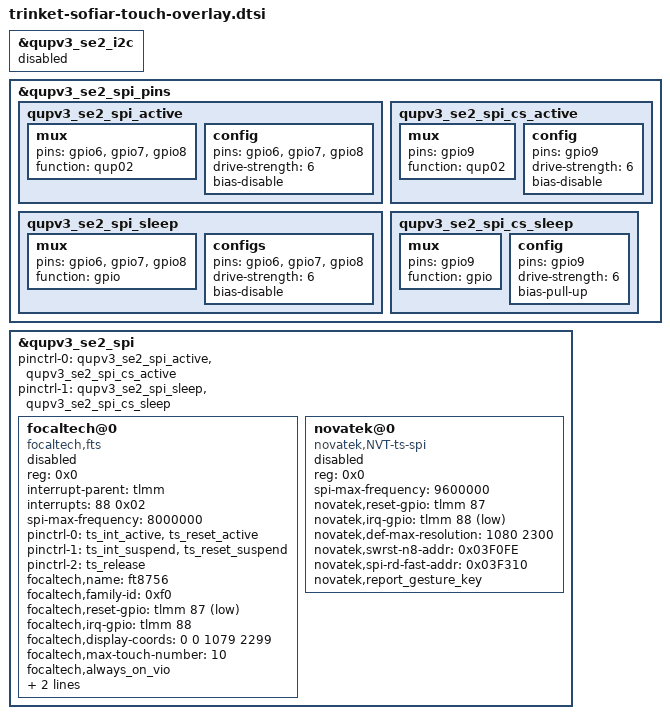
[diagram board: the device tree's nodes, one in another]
&qupv3_se2_i2c {
	status = "disabled";
};

&qupv3_se2_spi_pins {
	qupv3_se2_spi_active: qupv3_se2_spi_active {
		mux {
			pins = "gpio6", "gpio7", "gpio8";
			function = "qup02";
		};

		config {
			pins = "gpio6", "gpio7", "gpio8";
			drive-strength = <6>;
			bias-disable;
		};
	};

	qupv3_se2_spi_sleep: qupv3_se2_spi_sleep {
		mux {
			pins = "gpio6", "gpio7", "gpio8";
			function = "gpio";
		};

		configs {
			pins = "gpio6", "gpio7", "gpio8";
			drive-strength = <6>;
			bias-disable;
		};
	};

	qupv3_se2_spi_cs_active: qupv3_se2_spi_cs_active {
		mux {
			pins = "gpio9";
			function = "qup02";
		};

		config {
			pins = "gpio9";
			drive-strength = <6>;
			bias-disable;
		};
	};

	qupv3_se2_spi_cs_sleep: qupv3_se2_spi_cs_sleep {
		mux {
			pins = "gpio9";
			function = "gpio";
		};

		config {
			pins = "gpio9";
			drive-strength = <6>;
			bias-pull-up;
		};
	};
};

&qupv3_se2_spi {
	status = "ok";
	pinctrl-0 = <&qupv3_se2_spi_active &qupv3_se2_spi_cs_active>;
	pinctrl-1 = <&qupv3_se2_spi_sleep &qupv3_se2_spi_cs_sleep>;

	focaltech@0 {
		compatible = "focaltech,fts";
		reg = <0x0>;
		interrupt-parent = <&tlmm>;
		interrupts = <88 0x02>;
		spi-max-frequency=<8000000>;
		pinctrl-names = "pmx_ts_active","pmx_ts_suspend","pmx_ts_release";
		pinctrl-0 = <&ts_int_active &ts_reset_active>;
		pinctrl-1 = <&ts_int_suspend &ts_reset_suspend>;
		pinctrl-2 = <&ts_release>;
		focaltech,name = "ft8756";
		focaltech,family-id = <0xf0>;
		focaltech,reset-gpio = <&tlmm 87 0x01>;
		focaltech,irq-gpio = <&tlmm 88 0x02>;
		focaltech,display-coords = <0 0 1079 2299>;
		focaltech,max-touch-number = <10>;
		focaltech,always_on_vio;
		focaltech,dlfw_in_resume;
		focaltech,report_gesture_key;
		status = "/chosen", "mmi,panel_name", "tm_ft8756_fhd_vid";
	};

	novatek@0 {
		compatible = "novatek,NVT-ts-spi";
		reg = <0x0>;
		spi-max-frequency = <9600000>;  /* 4800000,9600000,15000000,19200000 */
		novatek,reset-gpio = <&tlmm 87 0x00>;
		novatek,irq-gpio = <&tlmm 88 0x2001>;
		novatek,def-max-resolution = <1080 2300>;
		novatek,swrst-n8-addr = <0x03F0FE>;
		novatek,spi-rd-fast-addr = <0x03F310>;
		novatek,report_gesture_key;
		status = "/chosen", "mmi,panel_name", "auo_nt36675_fhd_vid";
	};
};

